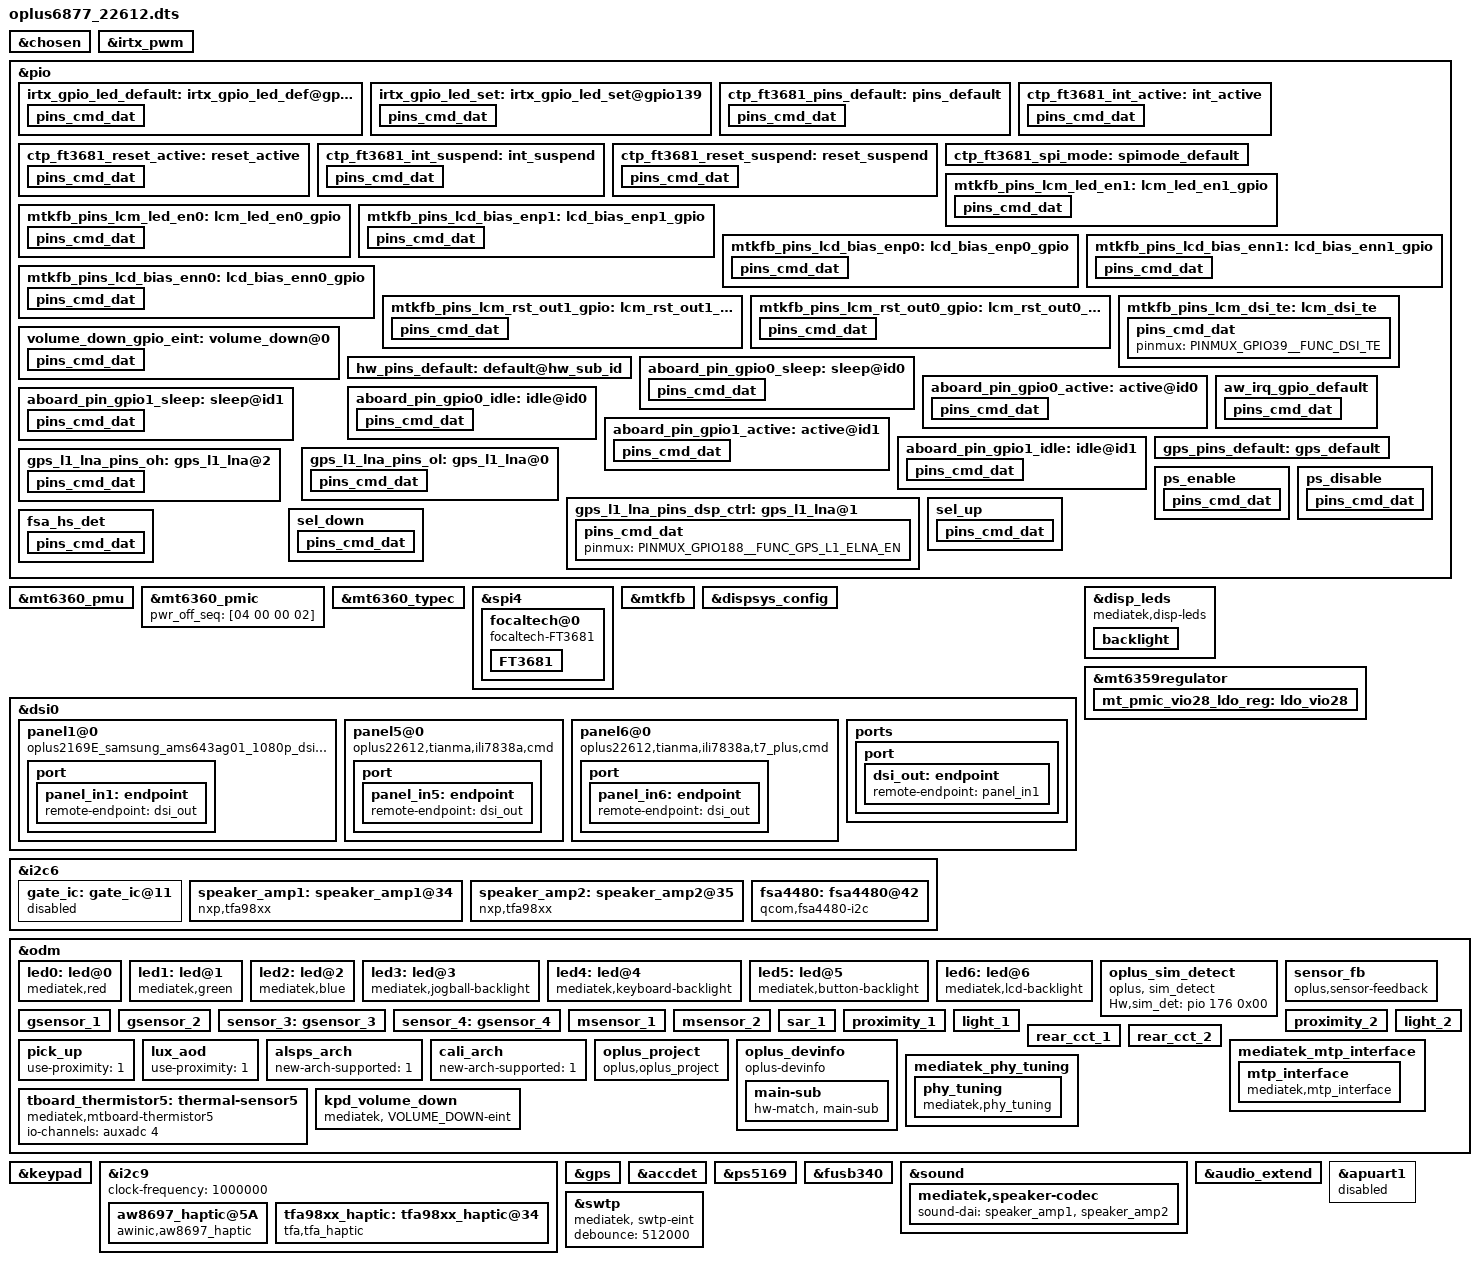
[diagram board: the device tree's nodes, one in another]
/*
 * Mediatek's mt6853 SoC device tree source
 *
 * Copyright (C) 2016 MediaTek Inc.
 *
 * This program is free software; you can redistribute it and/or modify
 * it under the terms of the GNU General Public License version 2 as
 * published by the Free Software Foundation.
 *
 * This program is distributed in the hope that it will be useful,
 * but WITHOUT ANY WARRANTY; without even the implied warranty of
 * MERCHANTABILITY or FITNESS FOR A PARTICULAR PURPOSE.
 * See http://www.gnu.org/licenses/gpl-2.0.html for more details.
 */
/dts-v1/;
/plugin/;
#include <dt-bindings/interrupt-controller/irq.h>
#include <dt-bindings/interrupt-controller/arm-gic.h>
#include <dt-bindings/pinctrl/mt6877-pinfunc.h>

/* #ifdef CONFIG_UFF_FINGERPRINT */
#include "mediatek/oplus_uff_22612.dtsi"
/* #endif CONFIG_UFF_FINGERPRINT */

/* chosen */
&chosen {
	atag,videolfb-fb_base_l = <0x7e605000>;
	atag,videolfb-fb_base_h = <0x0>;
	atag,videolfb-islcmfound = <1>;
	atag,videolfb-islcm_inited = <0>;
	atag,videolfb-fps= <6000>;
	atag,videolfb-vramSize= <0x1be0000>;
	atag,videolfb-lcmname=
		"td4330_fhdp_dsi_cmd_auo_rt4831_drv";
};

/* IRTX GPIO Start */
&irtx_pwm {
	pinctrl-names = "irtx_gpio_led_default", "irtx_gpio_led_set";
	pinctrl-0 = <&irtx_gpio_led_default>;
	pinctrl-1 = <&irtx_gpio_led_set>;
	status = "okay";
};
&pio {
	/* IRTX GPIO Settings -Start */
	/* default: GPIO0, output, high */
	irtx_gpio_led_default:irtx_gpio_led_def@gpio139 {
		pins_cmd_dat {
			pinmux = <PINMUX_GPIO139__FUNC_GPIO139>;
			slew-rate = <1>;
			bias-disable;
			output-low;
			input-schmitt-enable = <0>;
		};
	};

	irtx_gpio_led_set:irtx_gpio_led_set@gpio139 {
		pins_cmd_dat {
			pinmux = <PINMUX_GPIO139__FUNC_PWM_1>;
			slew-rate = <1>;
			output-high;
		};
	};
}; /* IRTX GPIO Settings -End */

&mt6360_pmu {
	mt6360,intr_gpio_num = <4>; /* direct defined GPIO num */
	mt6360,intr_gpio = <&pio 4 0x0>;
};

&mt6360_pmic {
	pwr_off_seq = [04 00 00 02];
};

&mt6360_typec {
	mt6360pd,intr_gpio_num = <5>; /* direct defined GPIO num */
	mt6360pd,intr_gpio = <&pio 5 0x0>;
};

&spi4 {
	status = "okay";
	#address-cells = <1>;
	#size-cells = <0>;
	
	pinctrl-names = "default",  "ft3681_int_active",
		"ft3681_reset_active", "ft3681_int_suspend",
		"ft3681_reset_suspend", "ft3681_spi_mode";
	pinctrl-0 = <&ctp_ft3681_pins_default>;
	pinctrl-1 = <&ctp_ft3681_int_active>;
	pinctrl-2 = <&ctp_ft3681_reset_active>;
	pinctrl-3 = <&ctp_ft3681_int_suspend>;
	pinctrl-4 = <&ctp_ft3681_reset_suspend>;
	pinctrl-5 = <&ctp_ft3681_spi_mode>;

	focaltech@0{
		compatible = "focaltech-FT3681";
		reg = <0x0>;
		chip-name = "FT3681";
		status = "okay";
		spi-max-frequency = <6000000>;
		/* Interrupt && Irq-gpio */
		interrupt-parent = <&pio>;
		interrupts = <14 0x2002>;

		/* Power Config */
		
		vdd_2v8-supply  = <&mt_pmic_vtp_ldo_reg>;
		vdd_2v8_volt = <3000000>;
		vcc_1v8-supply  = <&mt_pmic_vfp_ldo_reg>;
		vcc_1v8_volt = <1800000>;
		

		/* Other HW Resource */

		irq-gpio = <&pio 14 0x2002>;
		reset-gpio = <&pio 15 0x1>;

		touchpanel,max-num-support = <10>;
		touchpanel,tx-rx-num = <16 36>;
		earsense,tx-rx-num = <17 18>;
		touchpanel,panel-coords = <8640 19296>;
		touchpanel,display-coords = <1080 2412>;
		touchpanel,touchmajor-limit = <128 216>;
		touchpanel,elimination-range = <20 200 200>;
		//touchpanel,int-mode = <1>; /*0: interrupt and disable, 1:interrupt and not disable*/
		touchpanel,smooth-level = <0 1 2 3 8 10>;
		touchpanel,sensitive-level = <0 88 70 64 45 10>;
		touchpanel,tp-index = <0>;
		touchpanel,high-frame-rate-time = <60>;

		vid_len = <2>;
		//firmware_name = "0xAB30500";
		tp_type = <7>; /* panel-TIANMA*/
		platform_support_project = <22693 22694 22612>;
		platform_support_project_dir = <22612 22612 22612>;
		platform_support_project_commandline = "default_commandline","default_commandline","default_commandline";

		prevention,curved_screen_V2;
		prevention,grip_disable_level = <6>;
		prevention,updelay_time_ms = <30>;
		prevention,makeup_cnt_weight = <5 1 2 2 2>;
		prevention,large_corner_range = <960 2400>;
		prevention,large_corner_judge_condition = <850 100 800 5 5>;
		prevention,trx_reject_condition = <8 7 7>;
		prevention,trx_strict_reject_condition = <6 5 5>;
		prevention,large_judge_time_ms = <500 50 30>;
		prevention,large_exit_condition = <7 7 2>;
		prevention,single_channel_width = <8640 19296>;
		prevention,normal_tap_condition = <10 350>;
		prevention,long_edge_condition = <800 500 180 20>;
		prevention,long_strict_edge_condition = <400 200>;
		prevention,long_fingerhold_condition = <70 6 4 4>;
		prevention,short_edge_condition = <100 90 180 20>;
		prevention,short_strict_edge_condition = <100 60>;
		prevention,large_strict_exit_condition = <5 5>;
		prevention,top_corner_config = <250 750 100>;
		prevention,edge_swipe_config = <150 500>;

		/* SW Support Feature Control */
		//esd_handle_support;
		//register-is-16bit;
		//wireless_charger_support;
		headset_pump_support;
		//fw_edge_limit_support;

		health_monitor_v2_support;
		black_gesture_support;
		charger_pump_support;
		lcd_tp_refresh_support;
		fw_update_app_support;
		smart_gesture_support;
		game_switch_support;
		report_flow_unlock_support;
		kernel_grip_support;
		fingerprint_underscreen_support;
		pressure_report_support;
		touchpanel,single-optimized-time = <8>;
		report_rate_white_list_support;
		auto_test_force_pass_support;
		snr_read_support;
		high_resolution_support;
		algorithm_support;
		screenoff_fingerprint_info_support;

		/*
		 *Virtual Key Config:
		 *1:touchpanel,button-type: <virtualkey_type  supportted_button-map>
		 *virtualkey_type:
		 *Type 1: using board_properties
		 *Type 2: using same IC (button zone&& touch zone are seprate)
		 *Type 3: using diffrent IC (button zone&& touch zone are seprate)
		 *Type 4: No need of virtual key process
		 *supportted_button-map:select|menu|home|back
		 *
		 *2:touchpanel,button-map
		 *type (X1,Y1)(X2,Y2)(X3,Y3)(Width_X,Hight_Y)--Only when button-type is 0
		 */
		touchpanel,button-type = <4>;
		touchpanel.button-TRx = <0 0>;

		FT3681 {
			report_rate_default = <60>;
			report_rate_game_value = <0x02>;
		};
	};
};

&pio {
	ctp_ft3681_pins_default: pins_default {
		pins_cmd_dat {
			pinmux = <PINMUX_GPIO12__FUNC_SPI4_MI>,
				<PINMUX_GPIO13__FUNC_SPI4_MO>,
				<PINMUX_GPIO64__FUNC_SPI4_CLK>,
				<PINMUX_GPIO65__FUNC_SPI4_CSB>;
			drive-strength = <2>;
		};
	};
	ctp_ft3681_int_active: int_active {
		pins_cmd_dat {
			pinmux = <PINMUX_GPIO14__FUNC_GPIO14>;
			input-enable;
		};
	};
	ctp_ft3681_reset_active: reset_active {
		pins_cmd_dat {
			pinmux = <PINMUX_GPIO15__FUNC_GPIO15>;
			output-high;
		};
	};
	ctp_ft3681_int_suspend: int_suspend {
		pins_cmd_dat {
			pinmux = <PINMUX_GPIO14__FUNC_GPIO14>;
			output-low;
		};
	};
	ctp_ft3681_reset_suspend: reset_suspend {
		pins_cmd_dat {
			pinmux = <PINMUX_GPIO15__FUNC_GPIO15>;
			output-low;
		};
	};
	ctp_ft3681_spi_mode: spimode_default {
	};
};
/*touch end*/

&pio {
	mtkfb_pins_lcm_led_en1: lcm_led_en1_gpio {
		pins_cmd_dat {
			pinmux = <PINMUX_GPIO107__FUNC_GPIO107>;
			slew-rate = <1>;
			output-high;
		};
	};

	mtkfb_pins_lcm_led_en0: lcm_led_en0_gpio {
		pins_cmd_dat {
			pinmux = <PINMUX_GPIO107__FUNC_GPIO107>;
			slew-rate = <1>;
			output-low;
		};
	};

	mtkfb_pins_lcd_bias_enp1: lcd_bias_enp1_gpio {
		pins_cmd_dat {
			pinmux = <PINMUX_GPIO108__FUNC_GPIO108>;
			slew-rate = <1>;
			output-high;
		};
	};

	mtkfb_pins_lcd_bias_enp0: lcd_bias_enp0_gpio {
		pins_cmd_dat {
			pinmux = <PINMUX_GPIO108__FUNC_GPIO108>;
			slew-rate = <1>;
			output-low;
		};
	};

	mtkfb_pins_lcd_bias_enn1: lcd_bias_enn1_gpio {
		pins_cmd_dat {
			pinmux = <PINMUX_GPIO111__FUNC_GPIO111>;
			slew-rate = <1>;
			output-high;
		};
	};

	mtkfb_pins_lcd_bias_enn0: lcd_bias_enn0_gpio {
		pins_cmd_dat {
			pinmux = <PINMUX_GPIO111__FUNC_GPIO111>;
			slew-rate = <1>;
			output-low;
		};
	};

	mtkfb_pins_lcm_rst_out1_gpio: lcm_rst_out1_gpio {
		pins_cmd_dat {
			pinmux = <PINMUX_GPIO40__FUNC_GPIO40>;
			slew-rate = <1>;
			output-high;
		};
	};

	mtkfb_pins_lcm_rst_out0_gpio: lcm_rst_out0_gpio {
		pins_cmd_dat {
			pinmux = <PINMUX_GPIO40__FUNC_GPIO40>;
			slew-rate = <1>;
			output-low;
		};
	};
	mtkfb_pins_lcm_dsi_te: lcm_dsi_te {
		pins_cmd_dat {
			pinmux = <PINMUX_GPIO39__FUNC_DSI_TE>;
		};
	};
};

&mtkfb {
	pinctrl-names = "lcm_led_en1_gpio", "lcm_led_en0_gpio",
		"lcd_bias_enp1_gpio", "lcd_bias_enp0_gpio",
		"lcd_bias_enn1_gpio", "lcd_bias_enn0_gpio",
		"lcm_rst_out1_gpio", "lcm_rst_out0_gpio",
		"mode_te_te";
	pinctrl-0 = <&mtkfb_pins_lcm_led_en1>;
	pinctrl-1 = <&mtkfb_pins_lcm_led_en0>;
	pinctrl-2 = <&mtkfb_pins_lcd_bias_enp1>;
	pinctrl-3 = <&mtkfb_pins_lcd_bias_enp0>;
	pinctrl-4 = <&mtkfb_pins_lcd_bias_enn1>;
	pinctrl-5 = <&mtkfb_pins_lcd_bias_enn0>;
	pinctrl-6 = <&mtkfb_pins_lcm_rst_out1_gpio>;
	pinctrl-7 = <&mtkfb_pins_lcm_rst_out0_gpio>;
	pinctrl-8 = <&mtkfb_pins_lcm_dsi_te>;
	status = "okay";
};
&dispsys_config {
	pinctrl-names =
		"lcm_rst_out1_gpio", "lcm_rst_out0_gpio",
		"mode_te_te";
	pinctrl-0 = <&mtkfb_pins_lcm_rst_out1_gpio>;
	pinctrl-1 = <&mtkfb_pins_lcm_rst_out0_gpio>;
	pinctrl-2 = <&mtkfb_pins_lcm_dsi_te>;
	status = "okay";
};

&dsi0 {
	status = "okay";
	#address-cells = <1>;
	#size-cells = <0>;
	panel1@0 {
		compatible = "oplus2169E_samsung_ams643ag01_1080p_dsi_cmd,lcm";
		reg = <0>;
		//pm-enable-gpios = <&pio 39 0>;
		reset-gpios = <&pio 40 0>;
		bias-gpios = <&pio 107 0>;
		ldo3-supply = <&mt_pmic_vmc_ldo_reg>;
		pinctrl-names = "default";
		port {
			panel_in1: endpoint {
				remote-endpoint = <&dsi_out>;
			};
		};
	};
	panel5@0 {
		compatible = "oplus22612,tianma,ili7838a,cmd";
		reg = <1>;
		vddr-enable-gpios = <&pio 107 0>;
                //pw-1p8-gpios = <&pio 213 0>;
                //pw-reset-gpios = <&pio 193 0>;
		reset-gpios = <&pio 40 0>;
		vddr-aod-en-gpios = <&pio 117 0>;
		ldo3-supply = <&mt_pmic_vmc_ldo_reg>;
                //pw-1p8-gpios = <&pio 213 0>;
                //pw-reset-gpios = <&pio 193 0>;
                //vmcldo-supply = <&mt6368_vmc>;
                //vufsldo-supply = <&mt6363_vufs18>; //VCI
                //vmchldo-supply = <&mt6368_vmch>;  //VDDI 3.0V
/* #if defined(CONFIG_PXLW_IRIS) */
                //irisreset-gpios = <&pio 193 0>;
                //irisabyp-gpios = <&pio 188 0>;
                //irisready-gpios = <&pio 189 0>;
/* #endif */
		pinctrl-names = "default";
		port {
			panel_in5: endpoint {
				remote-endpoint = <&dsi_out>;
			};
		};
        };
	panel6@0 {
                compatible = "oplus22612,tianma,ili7838a,t7_plus,cmd";
                reg = <2>;
                vddr-enable-gpios = <&pio 107 0>;
                reset-gpios = <&pio 40 0>;
                vddr-aod-en-gpios = <&pio 117 0>;
                ldo3-supply = <&mt_pmic_vmc_ldo_reg>;
                pinctrl-names = "default";
                port {
                        panel_in6: endpoint {
                                remote-endpoint = <&dsi_out>;
                        };
                };
        };
	ports {
		port {
			dsi_out: endpoint {
				remote-endpoint = <&panel_in1>;
			};
		};
	};
};

&i2c6 {
	gate_ic: gate_ic@11 {
		status = "disable";
	};
};

&disp_leds {
	compatible = "mediatek,disp-leds";
	backlight {
		label = "lcd-backlight";
		max-brightness = <4095>;
		led-bits = <12>;
		trans-bits = <12>;
		default-state = "on";
	};
};
&mt6359regulator {
	mt_pmic_vio28_ldo_reg: ldo_vio28 {
		regulator-name = "vio28";
		regulator-min-microvolt = <3300000>;
		regulator-max-microvolt = <3300000>;
		regulator-enable-ramp-delay = <1920>;
		};
};

&odm {
	led0:led@0 {
		compatible = "mediatek,red";
		led_mode = <0>;
		data = <1>;
		pwm_config = <0 0 0 0 0>;
	};
	led1:led@1 {
		compatible = "mediatek,green";
		led_mode = <0>;
		data = <1>;
		pwm_config = <0 0 0 0 0>;
	};
	led2:led@2 {
		compatible = "mediatek,blue";
		led_mode = <0>;
		data = <1>;
		pwm_config = <0 0 0 0 0>;
	};
	led3:led@3 {
		compatible = "mediatek,jogball-backlight";
		led_mode = <0>;
		data = <1>;
		pwm_config = <0 0 0 0 0>;
	};
	led4:led@4 {
		compatible = "mediatek,keyboard-backlight";
		led_mode = <0>;
		data = <1>;
		pwm_config = <0 0 0 0 0>;
	};
	led5:led@5 {
		compatible = "mediatek,button-backlight";
		led_mode = <0>;
		data = <1>;
		pwm_config = <0 0 0 0 0>;
	};
	led6:led@6 {
		compatible = "mediatek,lcd-backlight";
		led_mode = <4>;
		data = <1>;
		pwm_config = <0 1 0 0 0>;
	};
    oplus_sim_detect {
	    compatible = "oplus, sim_detect";
	    Hw,sim_det = <&pio 176 0x00>;
    };
/* sensor start */
	/*
	enum {
		LIS3DH,
		LSM6DS3,
		BMI160,
		LIS2HH12,
		LSM6DSM,
		BMI2XY,
		LSM6DSO,
		BMA4XY,
		SC7A20,
		ICM4X6XX,
	};
	*/
    sensor_fb: sensor_fb {
            compatible = "oplus,sensor-feedback";
    };

	gsensor_1: gsensor_1 {
		status = "okay";
		sensor_name = <7>;//ICM4X6XX
		i2c_num = <2>;
		i2c_addr = <0>;
		direction = <1>;
		eint_num = <1>;
		step_count_7_en = <1>;
		config_miso = <1>;
		correct_y_bias = <1>;
	};
	gsensor_2: gsensor_2 {
		status = "okay";
		sensor_name = <6>;//LSM6DSO
		device_name = "lsm6dso";
		i2c_num = <2>;
		i2c_addr = <0>;
		direction = <5>;
		eint_num = <20>;
		gyro_cali_version= <2>; //should be always v2 for lsm6dso
		acc_cali_range= <200 200 200>;
	};
	sensor_3: gsensor_3 {
		status = "okay";
		sensor_name = <11>;//ICM42607
		device_name = "icm4n607";
		i2c_num = <2>;
		i2c_addr = <0>;
		direction = <0>;
		eint_num = <3>;
		gyro_cali_version= <2>;
		acc_cali_range= <300 300 300>; //300mg
	};
	sensor_4: gsensor_4 {
		status = "okay";
		sensor_name = <5>;//BMI2XY
		device_name = "bmi2xy";
		i2c_num = <2>;
		i2c_addr = <0>;
		direction = <1>;
		eint_num = <1>;
		gyro_cali_version= <2>;
		acc_cali_range= <300 300 300>; //250mg
	};
	/*
	enum {
		AKM09911,
		MMC3530,
		MMC5603,
		MXG4300,
	};
	*/
	msensor_1: msensor_1 {
		status = "okay";
		sensor_name = <0>;//AKM09911
		i2c_num = <0>;
		i2c_addr = <12>;
		direction = <0>;
		eint_num = <0>;
		soft-mag-parameter = <10361 0 1218 0 40 1 1542 0 8695 0 82 0 568 0 554 1 10839 0>;
	};
	msensor_2: msensor_2 {
		status = "okay";
		sensor_name = <2>;//MMC5603
		i2c_num = <0>;
		i2c_addr = <48>;
		direction = <3>;
		eint_num = <0>;
		soft-mag-parameter = <10352 0 58 1 78 1 58 1 9262 0 65 0 78 0 65 1 10432 0>;
	};
	/*
	enum {
		SX933x
	};
	*/
	sar_1: sar_1 {
		status = "okay";
		sensor_name = <0>;//SX933x
		i2c_num = <0>;
		i2c_addr = <40>;
		direction = <4>;
		eint_num = <13>;
		channel_num = <2>;
		channel_0_min = <0>;
		channel_0_max = <70000>;
		channel_1_min = <0>;
		channel_1_max = <70000>;
		channel_2_min = <0>;
		channel_2_max = <70000>;
		channel_3_min = <0>;
		channel_3_max = <70000>;
		reg_table_num = <3>;
	};
	/*
	enum {
		TMD2725,
		APSD9922,
		STK3335,
		STK3331,
		STK2232,
		TCS3701,
		STK32600,
	};
	*/
	proximity_1: proximity_1 {
		status = "okay";
		sensor_name = <6>;//STK32600
		i2c_num = <0>;
		i2c_addr = <72>;
		direction = <4>;
		eint_num = <2>;
		low_step = <300>;
		high_step = <400>;
		low_limit = <400>;
		high_limit = <600>;
		dirty_low_step = <300>;
		dirty_high_step = <400>;
		ps_dirty_limit = <1800>;
		ps_ir_limit = <2000>;
		ps_adjust_min = <0>;
		ps_adjust_max = <1850>;
		sampling_count = <5>;
		step_max = <400>;
		step_min = <100>;
		step_div = <2000>;
		anti_shake_delta = <70>;
		dynamic_cali_max = <5000>;
		raw2offset_radio = <1000>;
		offset_max = <60000>;
		offset_range_min = <0>;
		offset_range_max = <65535>;
		force_cali_limit = <2000>;
		cali_jitter_limit = <30>;
		cal_offset_margin = <3000>;
		sensor-reg = <0x03 0x28>;
		is_use_force_cali = <1>;
	};
	light_1: light_1 {
		status = "okay";
		sensor_name = <6>;//STK32600
		i2c_num = <0>;
		i2c_addr = <72>;
		direction = <4>;
		eint_num = <2>;
		als_buffer_length =<8>;
		als_ratio = <110>;
		als_type = <2>;//<1-normal;2-under screen;3-normal needed compensation>
		device_name = "stk32600";
		use_als_c2 = <1>;
	};
	proximity_2: proximity_2 {
		status = "okay";
		sensor_name = <5>;//TCS3701
		i2c_num = <0>;
		i2c_addr = <57>;
		direction = <4>;
		eint_num = <2>;
		low_step = <300>;
		high_step = <400>;
		low_limit = <400>;
		high_limit = <600>;
		dirty_low_step = <180>;
		dirty_high_step = <250>;
		ps_dirty_limit = <1020>;
		ps_ir_limit = <500>;
		ps_adjust_min = <0>;
		ps_adjust_max = <600>;
		sampling_count = <5>;
		step_max = <400>;
		step_min = <110>;
		step_div = <1500>;
		anti_shake_delta = <80>;
		dynamic_cali_max = <1024>;
		raw2offset_radio = <31200>;
		offset_max = <250>;
		offset_range_min = <255>;
		offset_range_max = <255>;
		force_cali_limit = <2000>;
		cali_jitter_limit = <30>;
		cal_offset_margin = <120>;
		sensor-reg = <0xBC 0xFB 0xB9 0x1C>;
	};
	light_2: light_2 {
		status = "okay";
		sensor_name = <5>;//TCS3701
		i2c_num = <0>;
		i2c_addr = <57>;
		direction = <4>;
		eint_num = <2>;
		als_ratio = <140>;
		als_buffer_length = <10>;
		als_type = <2>;
		device_name = "tcs3701";
	};
	/*
	enum {
		STK37600,
		MN29005,
		TCS3408,
	};
	*/
	rear_cct_1: rear_cct_1 {
		status = "okay";
		sensor_name = <0>;//STK37600
		i2c_num = <1>;
		i2c_addr = <0x48>;
		direction = <0>;
		eint_num = <10>;
		available_sensor = <7>; // bit 0: rear als, bit 1: rear cct, bit 2: rear flicker
		gold_rear_cct_3k = <11083 14060 1700 488 64 42136>; // 3000k gold parameter
		gold_rear_cct_6k = <8488 13068 3928 372 64 42964>;  // 3000k gold parameter
		device_name = "stk37600";
		cct_coef_Lir = <9116000 0 259000 0 1711000 1 7351000 0 12875000 0
				1686000 0 3545000 0 6606000 0 51505000 0 3221000 1
				2492000 1 2826000 1>;
		cct_coef_Hir = <178000 1 14775000 1 36798000 1 13552000 0 24758000 0
				31340000 0 3274000 1 7368000 1 19817000 0 161000 1
				23000 0 392000 0>;
	};
	rear_cct_2: rear_cct_2 {
		status = "okay";
		sensor_name = <2>;//TCS3408
		i2c_num = <1>;
		i2c_addr = <0x39>;
		direction = <0>;
		eint_num = <10>;
		available_sensor = <7>; // bit 0: rear als, bit 1: rear cct, bit 2: rear flicker
		gold_rear_cct_3k = <5140 2597 1342 8413 3080 2101>; // 3000k gold parameter
		gold_rear_cct_6k = <3465 2885 2046 7898 2864 3986>;  // 3000k gold parameter
		device_name = "tcs3408";
	};
	pick_up: pick_up {
		status = "okay";
		use-proximity = <1>;
	};
	lux_aod: lux_aod {
		status = "okay";
		use-proximity = <1>;
	};
	alsps_arch: alsps_arch {
		status = "okay";
		new-arch-supported = <1>;
	};
	cali_arch: cali_arch {
		status = "okay";
		new-arch-supported = <1>;
	};
/* sensor end */

/* OPLUS_BUG_STABILITY oppo project start */
	oplus_project:oplus_project {
		compatible = "oplus,oplus_project";
	};
	oplus_devinfo:oplus_devinfo {
		compatible = "oplus-devinfo";

		pinctrl-names = "default", "aboard_gpio0_sleep", "aboard_gpio0_active", "aboard_gpio0_idle", "aboard_gpio1_sleep", "aboard_gpio1_active", "aboard_gpio1_idle";
		pinctrl-0 = <&hw_pins_default>;
		pinctrl-1 = <&aboard_pin_gpio0_sleep>;
		pinctrl-2 = <&aboard_pin_gpio0_active>;
		pinctrl-3 = <&aboard_pin_gpio0_idle>;
		pinctrl-4 = <&aboard_pin_gpio1_sleep>;
		pinctrl-5 = <&aboard_pin_gpio1_active>;
		pinctrl-6 = <&aboard_pin_gpio1_idle>;
		main-sub {
			use_tristate_gpio;
            compatible = "hw-match, main-sub";
			aboard-gpio0 = <&pio 121 0x00>;
			aboard-gpio1 = <&pio 139 0x00>;
			abard-patterns = <0 1 1 0>;
			/*main board*/
			match-projects = <0x2169E 0x2169F 0x216C9 0x216CA>;
        };
	};
/* OPLUS_BUG_STABILITY oppo project end */

	mediatek_mtp_interface:mediatek_mtp_interface {
		mtp_interface {
			compatible = "mediatek,mtp_interface";
			InterfaceClass = <255>;
			InterfaceSubClass = <255>;
			InterfaceProtocol = <0>;
	};
};
	mediatek_phy_tuning:mediatek_phy_tuning {
		phy_tuning {
			compatible = "mediatek,phy_tuning";
			u2_vrt_ref = <7>;
			u2_term_ref = <7>;
			u2_enhance = <2>;
			u2_discth = <0xE>;
			host_u2_vrt_ref = <5>;
			host_u2_term_ref = <5>;
			host_u2_enhance = <3>;
			host_u2_discth = <0xA>;
	};
};

	tboard_thermistor5: thermal-sensor5 {
		compatible = "mediatek,mtboard-thermistor5";
		io-channels = <&auxadc 4>;
		io-channel-names = "thermistor-ch4";
	};

	kpd_volume_down:kpd_volume_down {
		compatible = "mediatek, VOLUME_DOWN-eint";
		interrupt-parent = <&pio>;
		interrupts = <7 IRQ_TYPE_EDGE_FALLING 7 0>;
		debounce = <32000>;
		status = "okay";
	};

};

&keypad {
	keypad,volume-down	= <&pio 7 0x00>;
	pinctrl-names = "volume_down_as_int";
	pinctrl-0 = <&volume_down_gpio_eint>;
	status = "okay";
};

&pio {
	volume_down_gpio_eint:volume_down@0{
		pins_cmd_dat {
			pinmux = <PINMUX_GPIO7__FUNC_GPIO7>;
			slew-rate = <0>;  /*direction 0:in, 1:out*/
			input-enable;
		};
	};
};

&pio {
        hw_pins_default:default@hw_sub_id {
        };

        aboard_pin_gpio0_sleep:sleep@id0 {
                pins_cmd_dat {
                        pinmux = <PINMUX_GPIO121__FUNC_GPIO121>;
                        slew-rate = <0>;
                        bias-pull-down;
                        input-enable;
                };
        };

        aboard_pin_gpio0_active:active@id0 {
                pins_cmd_dat {
                        pinmux = <PINMUX_GPIO121__FUNC_GPIO121>;
                        slew-rate = <0>;
                        bias-pull-up;
                        input-enable;
                };
        };

        aboard_pin_gpio0_idle:idle@id0 {
                pins_cmd_dat {
                        pinmux = <PINMUX_GPIO121__FUNC_GPIO121>;
                        slew-rate = <0>;
                        bias-disable;
                        input-enable;
                };
        };
        aboard_pin_gpio1_sleep:sleep@id1 {
                pins_cmd_dat {
                        pinmux = <PINMUX_GPIO139__FUNC_GPIO139>;
                        slew-rate = <0>;
                        bias-pull-down;
                        input-enable;
                };
        };

        aboard_pin_gpio1_active:active@id1 {
                pins_cmd_dat {
                        pinmux = <PINMUX_GPIO139__FUNC_GPIO139>;
                        slew-rate = <0>;
                        bias-pull-up;
                        input-enable;
                };
        };

        aboard_pin_gpio1_idle:idle@id1 {
                pins_cmd_dat {
                        pinmux = <PINMUX_GPIO139__FUNC_GPIO139>;
                        slew-rate = <0>;
                        bias-disable;
                        input-enable;
                };
        };
};

&i2c9 {
    status = "okay";
	clock-frequency = <1000000>;

	/* AWINIC AW8697 Haptic */
	aw8697_haptic@5A {
		status = "okay";
		compatible = "awinic,aw8697_haptic";
		reg = <0x5A>;
		reset-gpio = <&pio 26 0x00>;
		irq-gpio = <&pio 30 0x00>;
		qcom,device_id = <815>;//aw86927
		qcom,aw86927_boost_voltage = /bits/ 8 <0x5E>;
		
		pinctrl-names = "default";
		pinctrl-0 = <&aw_irq_gpio_default>;
	};
};

&pio{
	aw_irq_gpio_default: aw_irq_gpio_default {		//check
		pins_cmd_dat {
			pinmux = <PINMUX_GPIO30__FUNC_GPIO30>;
			input-enable;
			bias-pull-up = <MTK_PUPD_SET_R1R0_10>;
		};
	};

};

/* GPS GPIO standardization start */
&pio {
	gps_pins_default: gps_default {
	};
	gps_l1_lna_pins_ol: gps_l1_lna@0 {
		pins_cmd_dat {
			pinmux = <PINMUX_GPIO188__FUNC_GPIO188>;
			output-low;
		};
	};
	gps_l1_lna_pins_dsp_ctrl: gps_l1_lna@1 {
		pins_cmd_dat {
			pinmux = <PINMUX_GPIO188__FUNC_GPS_L1_ELNA_EN>;
		};
	};
	gps_l1_lna_pins_oh: gps_l1_lna@2 {
		pins_cmd_dat {
			pinmux = <PINMUX_GPIO188__FUNC_GPIO188>;
			output-high;
		};
	};
	/*gps_l5_lna_pins_ol: gps_l5_lna@0 {
		pins_cmd_dat {
			pinmux = <PINMUX_GPIO111__FUNC_GPIO111>;
			output-low;
		};
	};
	gps_l5_lna_pins_dsp_ctrl: gps_l5_lna@1 {
		pins_cmd_dat {
			pinmux = <PINMUX_GPIO111__FUNC_GPS_L5_ELNA_EN>;
		};
	};
	gps_l5_lna_pins_oh: gps_l5_lna@2 {
		pins_cmd_dat {
			pinmux = <PINMUX_GPIO111__FUNC_GPIO111>;
			output-high;
		};
	};*/
};
&gps {
	pinctrl-names = "default",
		"gps_l1_lna_disable",
		"gps_l1_lna_dsp_ctrl",
		"gps_l1_lna_enable";
		//"gps_l5_lna_disable",
		//"gps_l5_lna_dsp_ctrl",
		//"gps_l5_lna_enable";
	pinctrl-0 = <&gps_pins_default>;
	pinctrl-1 = <&gps_l1_lna_pins_ol>;
	pinctrl-2 = <&gps_l1_lna_pins_dsp_ctrl>;
	pinctrl-3 = <&gps_l1_lna_pins_oh>;
	//pinctrl-4 = <&gps_l5_lna_pins_ol>;
	//pinctrl-5 = <&gps_l5_lna_pins_dsp_ctrl>;
	//pinctrl-6 = <&gps_l5_lna_pins_oh>;
	status = "okay";
};
/* GPS GPIO standardization end */

&accdet {
	/* accdet micbias voltage: 0x09:2.85v 0x08:2.8v 0x07,
	 * 2.7v;0x05,2.5v;0x02,1.9v
	 */
	accdet-mic-vol = <8>;
	/* accdet pwm_width, pwm_thresh, fall_delay, rise_delay
	 * debounce0, debounce1, debounce3, debounce4
	 * eint pwm_width, eint pwm_thresh
	 * eint deb(debounce0, debounce1, debounce2, debounce3), inv_debounce
	 */
	headset-mode-setting = <0x500 0x500 1 0x1f0
				0x800 0x800 0x20 0x44
				0x4 0x1
				0x5 0x3 0x3 0x5 0xe>;
	accdet-plugout-debounce = <1>;
	/*1:ACC mode, 2:low cost without in bias, 6:low cost with in bias*/
	accdet-mic-mode = <2>;
	/*0--MD_MAX--UP_MAX--DW_MAX*/
	headset-three-key-threshold = <0 82 170 306>;
	//#else
	//headset-three-key-threshold = <0 80 220 400>;
	//#endif
	headset-three-key-threshold-CDD = <0 121 192 600>;
	/*0--MD_MAX--VOICE_MAX--UP_MAX--DW_MAX*/
	headset-four-key-threshold = <0 58 121 192 400>;

	/* select VTH to 2v and 500k, use internal resitance */
	eint_use_ext_res = <0>;
	status = "okay";
};

&ps5169{
	pinctrl-names = "enable", "disable";
	pinctrl-0 = <&ps_enable>;
	pinctrl-1 = <&ps_disable>;
	status = "okay";
};

&fusb340 {
	pinctrl-names = "sel_up", "sel_down";
	pinctrl-0 = <&sel_up>;
	pinctrl-1 = <&sel_down>;
	status = "okay";
};

&pio {
	ps_enable: ps_enable {
		pins_cmd_dat {
			pinmux = <PINMUX_GPIO121__FUNC_GPIO121>;
			output-high;
		};
	};

	ps_disable: ps_disable {
		pins_cmd_dat {
			pinmux = <PINMUX_GPIO121__FUNC_GPIO121>;
			output-low;
		};
	};

	sel_up: sel_up {
		pins_cmd_dat {
			pinmux = <PINMUX_GPIO6__FUNC_GPIO6>;
			output-low;
		};
	};

	sel_down: sel_down {
		pins_cmd_dat {
			pinmux = <PINMUX_GPIO6__FUNC_GPIO6>;
			output-high;
		};
	};
};

&sound {
	mtk_spk_i2s_out = <3>;
	mtk_spk_i2s_in = <9>;
	mediatek,speaker-codec {
	sound-dai = <&speaker_amp1>,<&speaker_amp2>;
	};
};

//#ifdef OPLUS_TFA98XX
&i2c6 {
	speaker_amp1: speaker_amp1@34 {
		compatible = "nxp,tfa98xx";
		reg = <0x34>;
		reset-gpio = <&pio 31 0>;
		tfa_min_range = <5000>;
		tfa_max_range = <8000>;
		tfa_channel = <0>;
		status = "okay";
	};

	speaker_amp2: speaker_amp2@35 {
		compatible = "nxp,tfa98xx";
		reg = <0x35>;
		reset-gpio = <&pio 24 0>;
		tfa_min_range = <5000>;
		tfa_max_range = <8000>;
		tfa_channel = <1>;
		status = "okay";
	};
};

&audio_extend {
//for nxp speaker
	oplus,speaker-vendor = "nxp";
	oplus,speaker-i2s-id = <3>;
	oplus,speaker-i2s-id-in = <0>;
	oplus,speaker-codec-name = "tfa98xx.6-0034","tfa98xx.6-0035";
	oplus,speaker-codec-dai-name = "tfa98xx-aif-6-34","tfa98xx-aif-6-35";
};

&pio {
	fsa_hs_det: fsa_hs_det {
		pins_cmd_dat {
			pinmux = <PINMUX_GPIO166__FUNC_GPIO166>;
			slew-rate = <1>;  /*direction 0:in, 1:out*/
			output-high;
		};
	};
};

&i2c6 {
	fsa4480: fsa4480@42 {
		compatible = "qcom,fsa4480-i2c";
		reg = <0x42>;
		pinctrl-names = "default";
		pinctrl-0 = <&fsa_hs_det>;
		fsa4480,hs-det-gpio = <&pio 166 0>;
	};
};

&i2c9 {
	tfa98xx_haptic: tfa98xx_haptic@34 {
		compatible = "tfa,tfa_haptic";
		reg = <0x34>;
		reset-gpio = <&pio 32 0>;
		i2s-id = <1>;
		status = "okay";
	};
};

//#endif

&apuart1 {
	status = "disabled";
};

// 1 = ldo power, refer to oplus_fp_common.h

//#ifdef OPLUS_VENDOR_SWTP
&swtp {
    compatible = "mediatek, swtp-eint";
    debounce = <512000>;
};

//#endif  /*OPLUS_VENDOR_SWTP*/
#include <oplus6877_22612/cust.dtsi>
#include "mediatek/cust_mt6877_22612_charge.dtsi"
/*#include "mediatek/cust_mt6877_touch_1080x2300.dtsi"*/
#include "mediatek/cust_mt6877_camera_22693.dtsi"
#include "mediatek/nfc/mt6877_roma_st54h.dtsi"
/*End of this file, DO NOT ADD ANYTHING HERE*/

